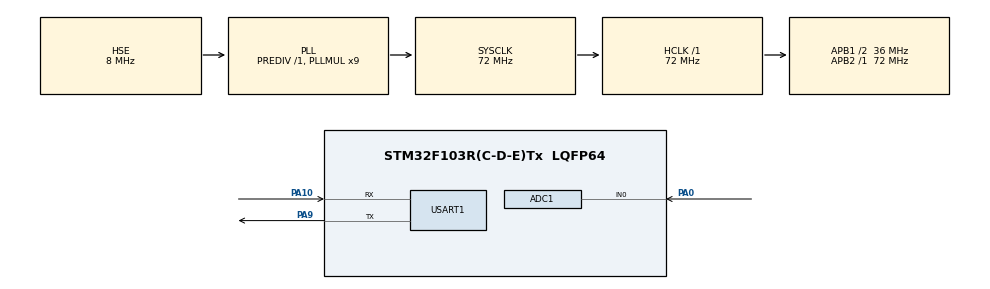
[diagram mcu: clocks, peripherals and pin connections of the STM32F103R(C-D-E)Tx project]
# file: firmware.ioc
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ADC1.Channel-0\#ChannelRegularConversion=ADC_CHANNEL_0
ADC1.NbrOfConversionFlag=1
ADC1.Rank-0\#ChannelRegularConversion=1
ADC1.SamplingTime-0\#ChannelRegularConversion=ADC_SAMPLETIME_1CYCLE_5
ADC1.master=1
FREERTOS.Queues01=RxByteQueue,128,uint8_t,0,Dynamic,NULL,NULL
FREERTOS.Tasks01=MotorTask,24,256,StartMotorTask,Default,NULL,Dynamic,NULL,NULL;SensorTask,24,256,StartSensorTask,Default,NULL,Dynamic,NULL,NULL;CommunicationTa,8,512,StartCommunicationTask,Default,NULL,Dynamic,NULL,NULL;UartRxTask,32,512,StartUartRxTask,Default,NULL,Dynamic,NULL,NULL
FREERTOS.configCHECK_FOR_STACK_OVERFLOW=2
FREERTOS.configTOTAL_HEAP_SIZE=8192
Mcu.Family=STM32F1
Mcu.Name=STM32F103R(C-D-E)Tx
Mcu.Package=LQFP64
NVIC.PriorityGroup=NVIC_PRIORITYGROUP_4
NVIC.TIM6_IRQn=true\:15\:0\:false\:false\:true\:false\:false\:true\:true
NVIC.TimeBase=TIM6_IRQn
NVIC.TimeBaseIP=TIM6
NVIC.USART1_IRQn=true\:5\:0\:false\:false\:true\:true\:true\:true\:true
PA0-WKUP.Signal=ADCx_IN0
PA10.Mode=Asynchronous
PA10.Signal=USART1_RX
PA13.Mode=Serial_Wire
PA13.Signal=SYS_JTMS-SWDIO
PA14.Mode=Serial_Wire
PA14.Signal=SYS_JTCK-SWCLK
PA9.Mode=Asynchronous
PA9.Signal=USART1_TX
PD0-OSC_IN.Mode=HSE-External-Oscillator
PD0-OSC_IN.Signal=RCC_OSC_IN
PD1-OSC_OUT.Mode=HSE-External-Oscillator
PD1-OSC_OUT.Signal=RCC_OSC_OUT
ProjectManager.HeapSize=0x200
ProjectManager.StackSize=0x400
ProjectManager.TargetToolchain=STM32CubeIDE
RCC.ADCPresc=RCC_ADCPCLK2_DIV6
RCC.AHBFreq_Value=72000000
RCC.APB1CLKDivider=RCC_HCLK_DIV2
RCC.APB1Freq_Value=36000000
RCC.APB1TimFreq_Value=72000000
RCC.APB2Freq_Value=72000000
RCC.APB2TimFreq_Value=72000000
RCC.HCLKFreq_Value=72000000
RCC.PLLMUL=RCC_PLL_MUL9
RCC.PLLSourceVirtual=RCC_PLLSOURCE_HSE
RCC.SYSCLKFreq_VALUE=72000000
RCC.SYSCLKSource=RCC_SYSCLKSOURCE_PLLCLK
RCC.USBFreq_Value=72000000
SH.ADCx_IN0.0=ADC1_IN0,IN0
USART1.VirtualMode=VM_ASYNC
VP_FREERTOS_VS_CMSIS_V2.Mode=CMSIS_V2
VP_SYS_VS_tim6.Mode=TIM6
board=custom

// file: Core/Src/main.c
/* USER CODE BEGIN Header */
/**
  ******************************************************************************
  * @file           : main.c
  * @brief          : Main program body
  ******************************************************************************
  * @attention
  *
  * Copyright (c) 2026 STMicroelectronics.
  * All rights reserved.
  *
  * This software is licensed under terms that can be found in the LICENSE file
  * in the root directory of this software component.
  * If no LICENSE file comes with this software, it is provided AS-IS.
  *
  ******************************************************************************
  */
/* USER CODE END Header */
#include "main.h"
#include "cmsis_os.h"

/* USER CODE BEGIN Includes */
#include <stdio.h>
/* USER CODE END Includes */

ADC_HandleTypeDef hadc1;

UART_HandleTypeDef huart1;

/* Definitions for MotorTask */
osThreadId_t MotorTaskHandle;
const osThreadAttr_t MotorTask_attributes = {
  .name = "MotorTask",
  .stack_size = 256 * 4,
  .priority = (osPriority_t) osPriorityNormal,
};
/* Definitions for SensorTask */
osThreadId_t SensorTaskHandle;
const osThreadAttr_t SensorTask_attributes = {
  .name = "SensorTask",
  .stack_size = 256 * 4,
  .priority = (osPriority_t) osPriorityNormal,
};
/* Definitions for CommunicationTa */
osThreadId_t CommunicationTaHandle;
const osThreadAttr_t CommunicationTa_attributes = {
  .name = "CommunicationTa",
  .stack_size = 512 * 4,
  .priority = (osPriority_t) osPriorityLow,
};
/* Definitions for UartRxTask */
osThreadId_t UartRxTaskHandle;
const osThreadAttr_t UartRxTask_attributes = {
  .name = "UartRxTask",
  .stack_size = 512 * 4,
  .priority = (osPriority_t) osPriorityAboveNormal,
};
/* Definitions for RxByteQueue */
osMessageQueueId_t RxByteQueueHandle;
const osMessageQueueAttr_t RxByteQueue_attributes = {
  .name = "RxByteQueue"
};
/* USER CODE BEGIN PV */

volatile uint32_t motor_count = 0;
volatile uint32_t sensor_count = 0;
uint8_t rx_byte;
volatile uint32_t rx_drop_count = 0;
volatile uint32_t rx_rearm_error_count = 0;

/* USER CODE END PV */

void SystemClock_Config(void);
static void MX_GPIO_Init(void);
static void MX_ADC1_Init(void);
static void MX_USART1_UART_Init(void);
void StartMotorTask(void *argument);
void StartSensorTask(void *argument);
void StartCommunicationTask(void *argument);
void StartUartRxTask(void *argument);

int main(void)
{

  /* MCU Configuration--------------------------------------------------------*/

  /* Reset of all peripherals, Initializes the Flash interface and the Systick. */
  HAL_Init();

  /* Configure the system clock */
  SystemClock_Config();

  /* Initialize all configured peripherals */
  MX_GPIO_Init();
  MX_ADC1_Init();
  MX_USART1_UART_Init();

  /* Init scheduler */
  osKernelInitialize();

  /* Create the queue(s) */
  /* creation of RxByteQueue */
  RxByteQueueHandle = osMessageQueueNew (128, sizeof(uint8_t), &RxByteQueue_attributes);

  /* Create the thread(s) */
  /* creation of MotorTask */
  MotorTaskHandle = osThreadNew(StartMotorTask, NULL, &MotorTask_attributes);

  /* creation of SensorTask */
  SensorTaskHandle = osThreadNew(StartSensorTask, NULL, &SensorTask_attributes);

  /* creation of CommunicationTa */
  CommunicationTaHandle = osThreadNew(StartCommunicationTask, NULL, &CommunicationTa_attributes);

  /* creation of UartRxTask */
  UartRxTaskHandle = osThreadNew(StartUartRxTask, NULL, &UartRxTask_attributes);

  /* Start scheduler */
  osKernelStart();

  /* We should never get here as control is now taken by the scheduler */

  /* Infinite loop */
  while (1)
  {

  }
}

void SystemClock_Config(void)
{
  RCC_OscInitTypeDef RCC_OscInitStruct = {0};
  RCC_ClkInitTypeDef RCC_ClkInitStruct = {0};
  RCC_PeriphCLKInitTypeDef PeriphClkInit = {0};

  /** Initializes the RCC Oscillators according to the specified parameters
  * in the RCC_OscInitTypeDef structure.
  */
  RCC_OscInitStruct.OscillatorType = RCC_OSCILLATORTYPE_HSE;
  RCC_OscInitStruct.HSEState = RCC_HSE_ON;
  RCC_OscInitStruct.HSEPredivValue = RCC_HSE_PREDIV_DIV1;
  RCC_OscInitStruct.HSIState = RCC_HSI_ON;
  RCC_OscInitStruct.PLL.PLLState = RCC_PLL_ON;
  RCC_OscInitStruct.PLL.PLLSource = RCC_PLLSOURCE_HSE;
  RCC_OscInitStruct.PLL.PLLMUL = RCC_PLL_MUL9;
  if (HAL_RCC_OscConfig(&RCC_OscInitStruct) != HAL_OK)
  {
    Error_Handler();
  }

  /** Initializes the CPU, AHB and APB buses clocks
  */
  RCC_ClkInitStruct.ClockType = RCC_CLOCKTYPE_HCLK|RCC_CLOCKTYPE_SYSCLK
                              |RCC_CLOCKTYPE_PCLK1|RCC_CLOCKTYPE_PCLK2;
  RCC_ClkInitStruct.SYSCLKSource = RCC_SYSCLKSOURCE_PLLCLK;
  RCC_ClkInitStruct.AHBCLKDivider = RCC_SYSCLK_DIV1;
  RCC_ClkInitStruct.APB1CLKDivider = RCC_HCLK_DIV2;
  RCC_ClkInitStruct.APB2CLKDivider = RCC_HCLK_DIV1;

  if (HAL_RCC_ClockConfig(&RCC_ClkInitStruct, FLASH_LATENCY_2) != HAL_OK)
  {
    Error_Handler();
  }
  PeriphClkInit.PeriphClockSelection = RCC_PERIPHCLK_ADC;
  PeriphClkInit.AdcClockSelection = RCC_ADCPCLK2_DIV6;
  if (HAL_RCCEx_PeriphCLKConfig(&PeriphClkInit) != HAL_OK)
  {
    Error_Handler();
  }
}

static void MX_ADC1_Init(void)
{

  ADC_ChannelConfTypeDef sConfig = {0};

  /** Common config
  */
  hadc1.Instance = ADC1;
  hadc1.Init.ScanConvMode = ADC_SCAN_DISABLE;
  hadc1.Init.ContinuousConvMode = DISABLE;
  hadc1.Init.DiscontinuousConvMode = DISABLE;
  hadc1.Init.ExternalTrigConv = ADC_SOFTWARE_START;
  hadc1.Init.DataAlign = ADC_DATAALIGN_RIGHT;
  hadc1.Init.NbrOfConversion = 1;
  if (HAL_ADC_Init(&hadc1) != HAL_OK)
  {
    Error_Handler();
  }

  /** Configure Regular Channel
  */
  sConfig.Channel = ADC_CHANNEL_0;
  sConfig.Rank = ADC_REGULAR_RANK_1;
  sConfig.SamplingTime = ADC_SAMPLETIME_1CYCLE_5;
  if (HAL_ADC_ConfigChannel(&hadc1, &sConfig) != HAL_OK)
  {
    Error_Handler();
  }

}

static void MX_USART1_UART_Init(void)
{

  huart1.Instance = USART1;
  huart1.Init.BaudRate = 115200;
  huart1.Init.WordLength = UART_WORDLENGTH_8B;
  huart1.Init.StopBits = UART_STOPBITS_1;
  huart1.Init.Parity = UART_PARITY_NONE;
  huart1.Init.Mode = UART_MODE_TX_RX;
  huart1.Init.HwFlowCtl = UART_HWCONTROL_NONE;
  huart1.Init.OverSampling = UART_OVERSAMPLING_16;
  if (HAL_UART_Init(&huart1) != HAL_OK)
  {
    Error_Handler();
  }

}

static void MX_GPIO_Init(void)
{

  /* GPIO Ports Clock Enable */
  __HAL_RCC_GPIOD_CLK_ENABLE();
  __HAL_RCC_GPIOA_CLK_ENABLE();

}

/* USER CODE BEGIN 4 */
void HAL_UART_RxCpltCallback(UART_HandleTypeDef *huart)
{
    if (huart->Instance == USART1)
    {
        if (osMessageQueuePut(RxByteQueueHandle,
                              &rx_byte, 0, 0) != osOK)
        {
            rx_drop_count++;
        }

        if (HAL_UART_Receive_IT(&huart1,
                                &rx_byte, 1) != HAL_OK)
        {
            rx_rearm_error_count++;
        }
    }
}
/* USER CODE END 4 */

void StartMotorTask(void *argument)
{
  /* USER CODE BEGIN 5 */
  /* Infinite loop */
  for(;;)
  {
	  motor_count++;
	  osDelay(10);
  }
  /* USER CODE END 5 */
}

void StartSensorTask(void *argument)
{
  /* USER CODE BEGIN StartSensorTask */
  /* Infinite loop */
  for(;;)
  {
	  sensor_count++;
	  osDelay(100);
  }
  /* USER CODE END StartSensorTask */
}

void StartCommunicationTask(void *argument)
{
  /* USER CODE BEGIN StartCommunicationTask */
  /* Infinite loop */
	char tx_buffer[100];

	    for (;;)
	    {
	        int len = snprintf(
	            tx_buffer,
	            sizeof(tx_buffer),
	            "Motor: %lu, Sensor: %lu\r\n",
	            (unsigned long)motor_count,
	            (unsigned long)sensor_count
	        );

	        if (len > 0 && len < sizeof(tx_buffer))
	        {
	            HAL_UART_Transmit(
	                &huart1,
	                (uint8_t *)tx_buffer,
	                len,
	                100
	            );
	        }

	        osDelay(500);
	    }
  /* USER CODE END StartCommunicationTask */
}

void StartUartRxTask(void *argument)
{
  for(;;)
  {
    osDelay(1);
  }
}

void HAL_TIM_PeriodElapsedCallback(TIM_HandleTypeDef *htim)
{
  if (htim->Instance == TIM6)
  {
    HAL_IncTick();
  }
}

void Error_Handler(void)
{
  __disable_irq();
  while (1)
  {
  }
}
